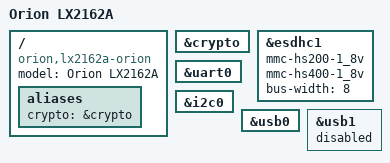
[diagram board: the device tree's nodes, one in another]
// SPDX-License-Identifier: (GPL-2.0 OR MIT)
//
// Device Tree file for LX2162A-Orion

/dts-v1/;

#include "fsl-lx2160a.dtsi"

/ {
	model = "Orion LX2162A";
	compatible = "orion,lx2162a-orion", "fsl,lx2160a";

	aliases {
		crypto = &crypto;
	};
};

&crypto {
	status = "okay";
};

&esdhc1 {
	mmc-hs200-1_8v;
	mmc-hs400-1_8v;
	bus-width = <8>;
	status = "okay";
};

&uart0 {
	status = "okay";
};

&i2c0 {
	status = "okay";
};

&usb0 {
	status = "okay";
};

&usb1 {
	status = "disabled";
};
